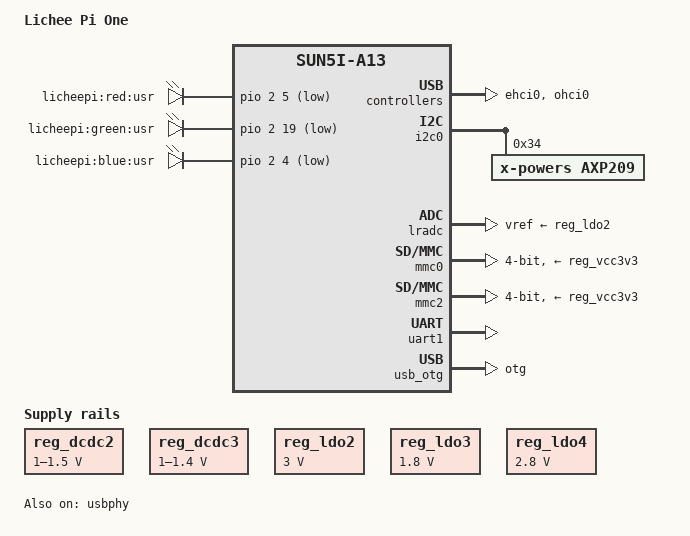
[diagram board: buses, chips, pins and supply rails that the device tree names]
/dts-v1/;
#include "sun5i-a13.dtsi"
#include "sunxi-common-regulators.dtsi"
#include <dt-bindings/gpio/gpio.h>
#include <dt-bindings/input/input.h>
/ {
	model = "Lichee Pi One";
	compatible = "licheepi,licheepi-one", "allwinner,sun5i-a13";
	aliases {
		serial0 = &uart1;
	};
	chosen {
		stdout-path = "serial0:115200n8";
	};
	leds {
		compatible = "gpio-leds";
		led-0 {
			label = "licheepi:red:usr";
			gpios = <&pio 2 5 GPIO_ACTIVE_LOW>;
		};
		led-1 {
			label = "licheepi:green:usr";
			gpios = <&pio 2 19 GPIO_ACTIVE_LOW>;
			default-state = "on";
		};
		led-2 {
			label = "licheepi:blue:usr";
			gpios = <&pio 2 4 GPIO_ACTIVE_LOW>;
		};
	};
};
&cpu0 {
	cpu-supply = <&reg_dcdc2>;
};
&ehci0 {
	status = "okay";
};
&i2c0 {
	status = "okay";
	axp209: pmic@34 {
		compatible = "x-powers,axp209";
		reg = <0x34>;
		interrupts = <0>;
		interrupt-controller;
		#interrupt-cells = <1>;
	};
};
&i2c1 {
	status = "disabled";
};
&i2c2 {
	status = "disabled";
};
&lradc {
	vref-supply = <&reg_ldo2>;
	status = "okay";
	button-984 {
		label = "Home";
		linux,code = <KEY_HOMEPAGE>;
		channel = <0>;
		voltage = <984126>;
	};
};
&mmc0 {
	vmmc-supply = <&reg_vcc3v3>;
	bus-width = <4>;
	broken-cd;
	status = "okay";
};
&mmc2 {
	pinctrl-names = "default";
	pinctrl-0 = <&mmc2_4bit_pc_pins>;
	vmmc-supply = <&reg_vcc3v3>;
	bus-width = <4>;
	broken-cd;
	status = "okay";
};
&ohci0 {
	status = "okay";
};
&otg_sram {
	status = "okay";
};
#include "axp209.dtsi"
&reg_dcdc2 {
	regulator-always-on;
	regulator-min-microvolt = <1000000>;
	regulator-max-microvolt = <1500000>;
	regulator-name = "vdd-cpu";
};
&reg_dcdc3 {
	regulator-always-on;
	regulator-min-microvolt = <1000000>;
	regulator-max-microvolt = <1400000>;
	regulator-name = "vdd-int-dll";
};
&reg_ldo1 {
	regulator-name = "vdd-rtc";
};
&reg_ldo2 {
	regulator-always-on;
	regulator-min-microvolt = <3000000>;
	regulator-max-microvolt = <3000000>;
	regulator-name = "avcc";
};
&reg_ldo3 {
	regulator-min-microvolt = <1800000>;
	regulator-max-microvolt = <1800000>;
	regulator-name = "csi-1.8v";
};
&reg_ldo4 {
	regulator-min-microvolt = <2800000>;
	regulator-max-microvolt = <2800000>;
	regulator-name = "csi-2.8v";
};
&reg_usb0_vbus {
	gpio = <&pio 2 12 GPIO_ACTIVE_HIGH>;  
	status = "okay";
};
&uart1 {
	pinctrl-names = "default";
	pinctrl-0 = <&uart1_pg_pins>;
	status = "okay";
};
&usb_otg {
	dr_mode = "otg";
	status = "okay";
};
&usbphy {
	usb0_id_det-gpios = <&pio 6 2 GPIO_ACTIVE_HIGH>;  
	usb0_vbus_det-gpios = <&pio 6 1 GPIO_ACTIVE_HIGH>;  
	usb0_vbus-supply = <&reg_usb0_vbus>;
	usb1_vbus-supply = <&reg_vcc5v0>;
	status = "okay";
};
